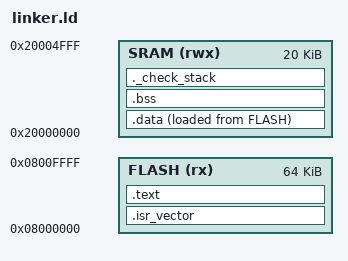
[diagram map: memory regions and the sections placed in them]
/**
 * STM32F103 Linker Script
 * For STM32F103C8T6: 64K Flash, 20K SRAM
 */

MEMORY
{
    FLASH (rx)  : ORIGIN = 0x08000000, LENGTH = 64K
    SRAM  (rwx) : ORIGIN = 0x20000000, LENGTH = 20K
}

_estack = ORIGIN(SRAM) + LENGTH(SRAM);

SECTIONS
{
    /* Vector table + code go into FLASH */
    .isr_vector :
    {
        . = ALIGN(4);
        KEEP(*(.isr_vector))
        . = ALIGN(4);
    } >FLASH

    .text :
    {
        . = ALIGN(4);
        *(.text)
        *(.text*)
        *(.rodata)
        *(.rodata*)
        . = ALIGN(4);
        _etext = .;
    } >FLASH

    /* Initialized data — stored in FLASH, copied to SRAM at startup */
    _sidata = LOADADDR(.data);

    .data :
    {
        . = ALIGN(4);
        _sdata = .;
        *(.data)
        *(.data*)
        . = ALIGN(4);
        _edata = .;
    } >SRAM AT> FLASH

    /* Uninitialized data — zeroed at startup */
    .bss :
    {
        . = ALIGN(4);
        _sbss = .;
        *(.bss)
        *(.bss*)
        *(COMMON)
        . = ALIGN(4);
        _ebss = .;
    } >SRAM

    /* Stack sanity check */
    ._check_stack :
    {
        . = ALIGN(4);
        . = . + 0x400; /* minimum 1KB stack */
        . = ALIGN(4);
    } >SRAM
}
